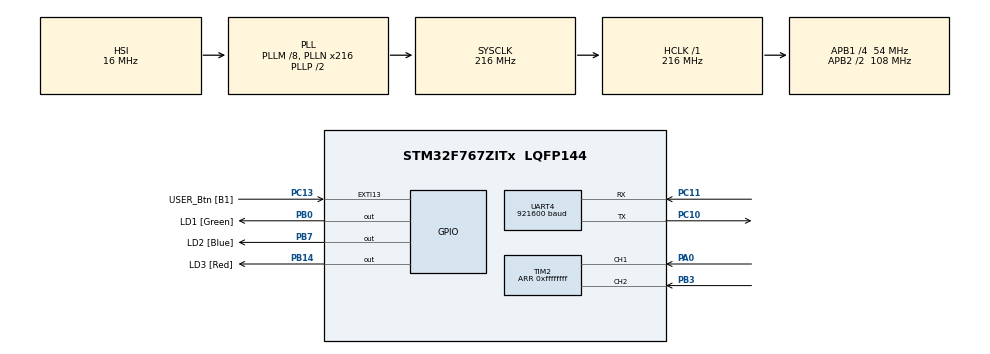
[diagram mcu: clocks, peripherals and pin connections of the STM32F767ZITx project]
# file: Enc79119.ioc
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Mcu.Family=STM32F7
RCC.CortexFreq_Value=216000000
PC10.Signal=UART4_TX
PB14.GPIO_Label=LD3 [Red]
PA14.GPIO_Label=TCK
RCC.SYSCLKSourceVirtual=RCC_SYSCLKSOURCE_PLLCLK
CORTEX_M7.PREFETCH_ENABLE=1
PA0/WKUP.Signal=S_TIM2_CH1_ETR
PB0.GPIO_Label=LD1 [Green]
TIM2.EncoderMode=TIM_ENCODERMODE_TI12
PC13.GPIO_Label=USER_Btn [B1]
PG13.Signal=ETH_TXD0
RCC.SYSCLKSource=RCC_SYSCLKSOURCE_PLLCLK
ProjectManager.StackSize=0x400
UART4.BaudRate=921600
UART4.Mode=MODE_TX
RCC.HCLKFreq_Value=216000000
RCC.APB2TimFreq_Value=216000000
RCC.AHBFreq_Value=216000000
RCC.HSE_VALUE=16000000
RCC.PLLMUL=RCC_PLL_MUL9
PB7.Signal=GPIO_Output
PB7.GPIO_Label=LD2 [Blue]
Mcu.Package=LQFP144
PC14/OSC32_IN.Signal=RCC_OSC32_IN
PC11.Mode=Asynchronous
RCC.APB2CLKDivider=RCC_HCLK_DIV2
RCC.APB1TimFreq_Value=108000000
CORTEX_M7.CPU_ICache=Enabled
PC13.Signal=GPXTI13
PC11.Signal=UART4_RX
PC10.Mode=Asynchronous
RCC.APB1CLKDivider=RCC_HCLK_DIV4
PG13.GPIO_Label=RMII_TXD0 [LAN8742A-CZ-TR_TXD0]
SH.S_TIM2_CH2.0=TIM2_CH2,Encoder_Interface
ProjectManager.TargetToolchain=STM32CubeIDE
CORTEX_M7.ART_ACCLERATOR_ENABLE=1
RCC.USBFreq_Value=216000000
RCC.LSE_VALUE=32768
PB14.Signal=GPIO_Output
board=NUCLEO-F767ZI
RCC.VCOOutputFreq_Value=432000000
RCC.APB2Freq_Value=108000000
RCC.PRESCALERUSB=RCC_USBCLKSOURCE_PLL_DIV1_5
TIM2.Period=0xffffffff
Mcu.Name=STM32F767ZITx
RCC.48MHZClocksFreq_Value=24000000
PB3.Signal=S_TIM2_CH2
RCC.SYSCLKFreq_VALUE=216000000
SH.S_TIM2_CH1_ETR.0=TIM2_CH1,Encoder_Interface
PA14.Signal=SYS_JTCK-SWCLK
ProjectManager.HeapSize=0x200
RCC.HSI_VALUE=16000000
NVIC.PriorityGroup=NVIC_PRIORITYGROUP_4
RCC.PLLM=8
RCC.PLLN=216
PC15/OSC32_OUT.Signal=RCC_OSC32_OUT
CORTEX_M7.CPU_DCache=Enabled
RCC.APB1Freq_Value=54000000
PB0.Signal=GPIO_Output

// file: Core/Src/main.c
/* USER CODE BEGIN Header */
/**
  ******************************************************************************
  * @file           : main.c
  * @brief          : Main program body
  ******************************************************************************
  * @attention
  *
  * <h2><center>&copy; Copyright (c) 2021 STMicroelectronics.
  * All rights reserved.</center></h2>
  *
  * This software component is licensed by ST under BSD 3-Clause license,
  * the "License"; You may not use this file except in compliance with the
  * License. You may obtain a copy of the License at:
  *                        opensource.org/licenses/BSD-3-Clause
  *
  ******************************************************************************
  */
/* USER CODE END Header */
#include "main.h"
#include "tim.h"
#include "usart.h"
#include "gpio.h"

/* USER CODE BEGIN PTD */
#define PI 3.1415926535f
/* USER CODE END PTD */

void SystemClock_Config(void);

/* USER CODE BEGIN 0 */
#include <string.h>
#include <stdio.h>
/* USER CODE END 0 */

int main(void)
{
  /* USER CODE BEGIN 1 */
	HAL_StatusTypeDef status;
			uint32_t TIM2_prev = 0; // предыдущ. значение
			// UART
			uint8_t pTxData[200];
  /* USER CODE END 1 */

  /* Enable I-Cache---------------------------------------------------------*/
  SCB_EnableICache();

  /* Enable D-Cache---------------------------------------------------------*/
  SCB_EnableDCache();

  /* MCU Configuration--------------------------------------------------------*/

  /* Reset of all peripherals, Initializes the Flash interface and the Systick. */
  HAL_Init();

  /* Configure the system clock */
  SystemClock_Config();

  /* Initialize all configured peripherals */
  MX_GPIO_Init();
  MX_TIM2_Init();
  MX_UART4_Init();
  /* USER CODE BEGIN 2 */
//  sprintf((char *)pTxData, "Hi UART in Encoder project!\r\n");
//      status = HAL_UART_Transmit (&huart4, pTxData, strlen((char *)pTxData), 200);
      status = HAL_TIM_Encoder_Start (&htim2, TIM_CHANNEL_ALL);
  /* USER CODE END 2 */

  /* Infinite loop */
  while (1)
  {
	  if(TIM2->CNT != TIM2_prev)
	  	  	 {
	  	  	  TIM2_prev = TIM2->CNT; // предыдущ. значение
	  	  	  	sprintf((char *)pTxData, "%ld\r\n", TIM2_prev);
	  	  		status = HAL_UART_Transmit (&huart4, pTxData, strlen((char *)pTxData), 200);
	  	  	 }
  }
}

void SystemClock_Config(void)
{
  RCC_OscInitTypeDef RCC_OscInitStruct = {0};
  RCC_ClkInitTypeDef RCC_ClkInitStruct = {0};
  RCC_PeriphCLKInitTypeDef PeriphClkInitStruct = {0};

  /** Configure the main internal regulator output voltage
  */
  __HAL_RCC_PWR_CLK_ENABLE();
  __HAL_PWR_VOLTAGESCALING_CONFIG(PWR_REGULATOR_VOLTAGE_SCALE1);
  /** Initializes the RCC Oscillators according to the specified parameters
  * in the RCC_OscInitTypeDef structure.
  */
  RCC_OscInitStruct.OscillatorType = RCC_OSCILLATORTYPE_HSI;
  RCC_OscInitStruct.HSIState = RCC_HSI_ON;
  RCC_OscInitStruct.HSICalibrationValue = RCC_HSICALIBRATION_DEFAULT;
  RCC_OscInitStruct.PLL.PLLState = RCC_PLL_ON;
  RCC_OscInitStruct.PLL.PLLSource = RCC_PLLSOURCE_HSI;
  RCC_OscInitStruct.PLL.PLLM = 8;
  RCC_OscInitStruct.PLL.PLLN = 216;
  RCC_OscInitStruct.PLL.PLLP = RCC_PLLP_DIV2;
  RCC_OscInitStruct.PLL.PLLQ = 2;
  if (HAL_RCC_OscConfig(&RCC_OscInitStruct) != HAL_OK)
  {
    Error_Handler();
  }
  /** Activate the Over-Drive mode
  */
  if (HAL_PWREx_EnableOverDrive() != HAL_OK)
  {
    Error_Handler();
  }
  /** Initializes the CPU, AHB and APB buses clocks
  */
  RCC_ClkInitStruct.ClockType = RCC_CLOCKTYPE_HCLK|RCC_CLOCKTYPE_SYSCLK
                              |RCC_CLOCKTYPE_PCLK1|RCC_CLOCKTYPE_PCLK2;
  RCC_ClkInitStruct.SYSCLKSource = RCC_SYSCLKSOURCE_PLLCLK;
  RCC_ClkInitStruct.AHBCLKDivider = RCC_SYSCLK_DIV1;
  RCC_ClkInitStruct.APB1CLKDivider = RCC_HCLK_DIV4;
  RCC_ClkInitStruct.APB2CLKDivider = RCC_HCLK_DIV2;

  if (HAL_RCC_ClockConfig(&RCC_ClkInitStruct, FLASH_LATENCY_7) != HAL_OK)
  {
    Error_Handler();
  }
  PeriphClkInitStruct.PeriphClockSelection = RCC_PERIPHCLK_UART4;
  PeriphClkInitStruct.Uart4ClockSelection = RCC_UART4CLKSOURCE_PCLK1;
  if (HAL_RCCEx_PeriphCLKConfig(&PeriphClkInitStruct) != HAL_OK)
  {
    Error_Handler();
  }
}

void Error_Handler(void)
{
  __disable_irq();
  while (1)
  {
  }
}

/************************ (C) COPYRIGHT STMicroelectronics *****END OF FILE****/
